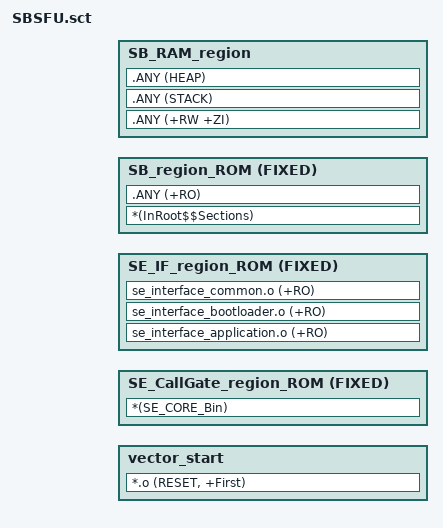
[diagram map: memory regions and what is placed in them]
#! armclang --target=arm-arm-none-eabi  -mcpu=cortex-m4 -E -xc
; *************************************************************
; *** Scatter-Loading Description File generated by uVision ***
; *************************************************************
#include "..\..\Linker_Common\MDK-ARM\mapping_sbsfu.h"
#include "..\..\Linker_Common\MDK-ARM\mapping_fwimg.h"

; *** regions needed by SBSFU project ***
LR_ROM_Vector ROM_START VECTOR_SIZE {
  vector_start ROM_START VECTOR_SIZE {
  *.o (RESET, +First)
  }
}

LR_ROM1 SE_CODE_REGION_ROM_START {
  SE_CallGate_region_ROM SE_CODE_REGION_ROM_START FIXED {
  *(SE_CORE_Bin)
  }
}

LR_IF SE_IF_REGION_ROM_START {  
  SE_IF_region_ROM SE_IF_REGION_ROM_START FIXED SE_IF_ROM_REGION_SIZE {
     se_interface_application.o (+RO)
	 se_interface_bootloader.o (+RO)
	 se_interface_common.o (+RO)
  }
  SB_region_ROM SB_REGION_ROM_START FIXED SB_ROM_REGION_SIZE {
  *(InRoot$$Sections)
  .ANY (+RO)
  }
  SB_RAM_region SB_REGION_RAM_START SB_RAM_REGION_SIZE  {
  .ANY (+RW +ZI)
  .ANY (STACK)
  .ANY (HEAP)
  }
}


